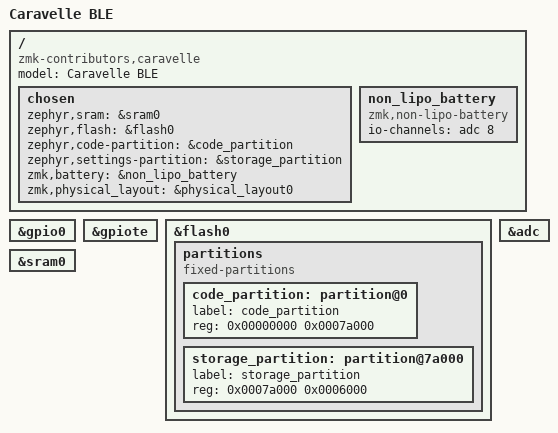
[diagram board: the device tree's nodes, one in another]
/* Minimal board DTS for Caravelle to allow devicetree preprocessing in CI.
 * Add peripherals/back references as needed later. */
/dts-v1/;
#include <nordic/nrf52832_qfaa.dtsi>
#include <dt-bindings/zmk/matrix_transform.h>

/ {
	model = "Caravelle BLE";
	compatible = "zmk-contributors,caravelle";

	chosen {
		zephyr,sram = &sram0;
		zephyr,flash = &flash0;
        zephyr,code-partition = &code_partition;
        zephyr,settings-partition = &storage_partition;
        zmk,battery = &non_lipo_battery;
        zmk,physical_layout = &physical_layout0;
	};

    non_lipo_battery: non_lipo_battery {
        compatible = "zmk,non-lipo-battery";
        io-channels = <&adc 8>;  // vdd
    }; 
};

&gpio0 {
	status = "okay";
};

&gpiote {
	status = "okay";
};

&flash0 {
    partitions {
        compatible = "fixed-partitions";
        #address-cells = <1>;
        #size-cells = <1>;

        /* 0x00000 から 0x7a000 (488KB) をコード領域に使用 */
        code_partition: partition@0 {
            label = "code_partition";
            reg = <0x00000000 0x0007a000>;
        };

        /* 0x7a000 から 0x6000 (24KB) を保存領域に使用 */
        storage_partition: partition@7a000 {
            label = "storage_partition";
            reg = <0x0007a000 0x0006000>;
        };
    };
};

&sram0 {
	status = "okay";
};

&adc {
	status ="okay";
};
